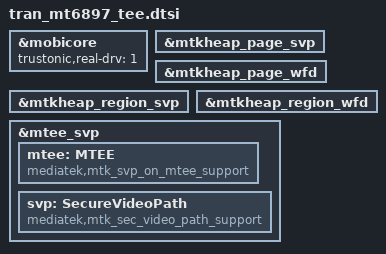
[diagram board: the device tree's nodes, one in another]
// SPDX-License-Identifier: GPL-2.0-only
/*
 * Copyright (C) 2024 Transsion Inc.
 */
/* Trustonic Mobicore real driver */
&mobicore {
        trustonic,real-drv = <1>;
};

&mtkheap_page_svp {
        status = "ok";
};

&mtkheap_page_wfd {
        status = "ok";
};

&mtkheap_region_svp {
        status = "ok";
};

&mtkheap_region_wfd {
        status = "ok";
};

&mtee_svp {
        mtee: MTEE {
                compatible = "mediatek,mtk_svp_on_mtee_support";
        };
        svp: SecureVideoPath {
                compatible = "mediatek,mtk_sec_video_path_support";
        };
};

